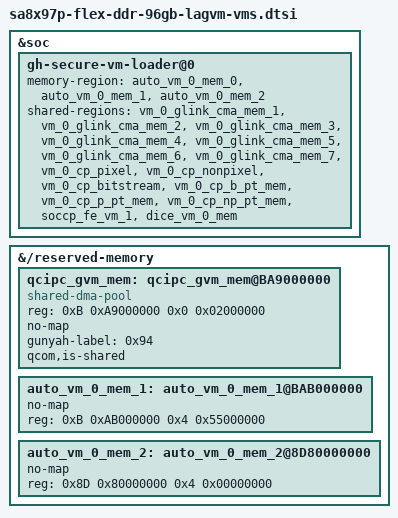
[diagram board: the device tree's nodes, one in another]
// SPDX-License-Identifier: BSD-3-Clause
/*
 * Copyright (c) Qualcomm Technologies, Inc. and/or its subsidiaries.
 */

#include "sa8x97p-vms-la.dtsi"

&soc {
	gh-secure-vm-loader@0 {
		memory-region = <&auto_vm_0_mem_0 &auto_vm_0_mem_1 &auto_vm_0_mem_2>;
		shared-regions = <&vm_0_glink_cma_mem_1
				&vm_0_glink_cma_mem_2
				&vm_0_glink_cma_mem_3
				&vm_0_glink_cma_mem_4
				&vm_0_glink_cma_mem_5
				&vm_0_glink_cma_mem_6
				&vm_0_glink_cma_mem_7
				&vm_0_cp_pixel
				&vm_0_cp_nonpixel
				&vm_0_cp_bitstream
				&vm_0_cp_b_pt_mem
				&vm_0_cp_p_pt_mem
				&vm_0_cp_np_pt_mem
				&soccp_fe_vm_1
				&dice_vm_0_mem>;
	};
};

&{/reserved-memory} {
	qcipc_gvm_mem: qcipc_gvm_mem@BA9000000 {
		compatible = "shared-dma-pool";
		reg = <0xB 0xA9000000 0x0 0x02000000>;
		no-map;
		gunyah-label = <0x94>;
		qcom,is-shared;
	};

	auto_vm_0_mem_1: auto_vm_0_mem_1@BAB000000 {
		no-map;
		reg = <0xB 0xAB000000 0x4 0x55000000>; /* 17744MB */
	};

	auto_vm_0_mem_2: auto_vm_0_mem_2@8D80000000 {
		no-map;
		reg = <0x8D 0x80000000 0x4 0x00000000>; /* 16384MB */
	};
};
